# STM32MP25_CM33 register map
File version: 1.3
CPU: CM33 r0p1, little endian, MPU, FPU, vendor SysTick, 8 interrupt priority bits
Registers are 32-bit, read-write, reset 0x0 unless marked. A register's access mark holds for its fields unless they carry their own. Offsets are from the block's base; [hi:lo] are bit positions; {n}, {i} and the like mark numbered series.

## I2C1 — I2C address block description
Base 0x40120000
Same registers: I2C2 0x40130000, I2C3 0x40140000, I2C4 0x40150000, I2C5 0x40160000, I2C6 0x40170000, I2C7 0x40180000, I2C8 0x46040000, I2C1_S 0x50120000, I2C2_S 0x50130000, I2C3_S 0x50140000, I2C4_S 0x50150000, I2C5_S 0x50160000, I2C6_S 0x50170000, I2C7_S 0x50180000, I2C8_S 0x56040000
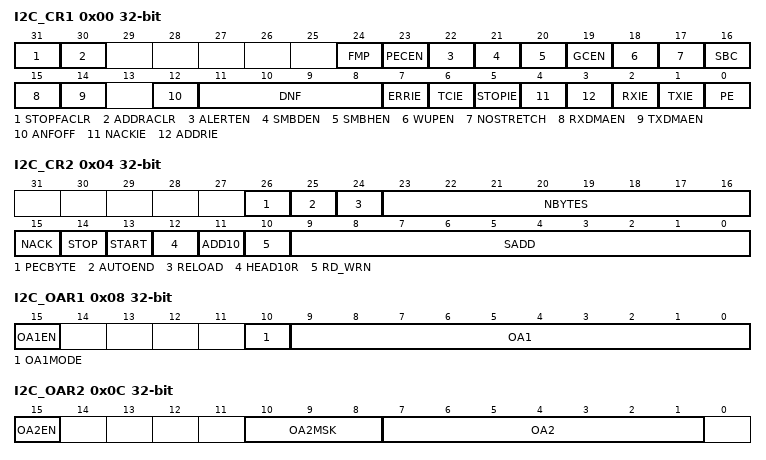
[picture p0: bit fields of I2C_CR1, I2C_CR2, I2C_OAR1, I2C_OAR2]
0x00 I2C_CR1 — I2C control register 1
  [31] STOPFACLR — STOP detection flag (STOPF) automatic clear
    0=STOPF flag is set by hardware, cleared by software by setting STOPCF bit; 1=STOPF flag remains cleared by hardware. This mode can be used in NOSTRETCH slave mode, to avoid the overrun error if the STOPF flag is not cleared before next data transmission. This allows a slave data management by DMA only, without any interrupt from peripheral.
  [30] ADDRACLR — Address match flag (ADDR) automatic clear
    0=ADDR flag is set by hardware, cleared by software by setting ADDRCF bit; 1=ADDR flag remains cleared by hardware. This mode can be used in slave mode, to avoid the ADDR clock stretching if the I2C enables only one slave address. This allows a slave data management by DMA only, without any interrupt from peripheral.
  [24] FMP — Fast-mode Plus 20 mA drive enable
    0=20 mA I/O drive disabled; 1=20 mA I/O drive enabled
  [23] PECEN — PEC enable Note: If the SMBus feature is not supported, this bit is reserved and forced by hardware to 0. Refer to Section75.3.
    0=PEC calculation disabled; 1=PEC calculation enabled
  [22] ALERTEN — SMBus alert enable Note: When ALERTEN = 0, the SMBA pin can be used as a standard GPIO. Note: If the SMBus feature is not supported, this bit is reserved and forced by hardware to 0. Refer to Section75.3.
    0=The SMBus alert pin (SMBA) is not supported in host mode (SMBHEN = 1). In device mode (SMBHEN = 0), the SMBA pin is released and the Alert Response Address header is disabled (0001100x followed by NACK).; 1=The SMBus alert pin is supported in host mode (SMBHEN = 1). In device mode (SMBHEN = 0), the SMBA pin is driven low and the Alert Response Address header is enabled (0001100x followed by ACK).
  [21] SMBDEN — SMBus device default address enable Note: If the SMBus feature is not supported, this bit is reserved and forced by hardware to 0. Refer to Section75.3.
    0=Device default address disabled. Address 0b1100001x is NACKed.; 1=Device default address enabled. Address 0b1100001x is ACKed.
  [20] SMBHEN — SMBus host address enable Note: If the SMBus feature is not supported, this bit is reserved and forced by hardware to 0. Refer to Section75.3.
    0=Host address disabled. Address 0b0001000x is NACKed.; 1=Host address enabled. Address 0b0001000x is ACKed.
  [19] GCEN — General call enable
    0=General call disabled. Address 0b00000000 is NACKed.; 1=General call enabled. Address 0b00000000 is ACKed.
  [18] WUPEN — Wake-up from Stop mode enable Note: If the wake-up from Stop mode feature is not supported, this bit is reserved and forced by hardware to 0. Refer to Section75.3. Note: WUPEN can be set only when DNF = 0000.
    0=Wake-up from Stop mode disabled; 1=Wake-up from Stop mode enabled
  [17] NOSTRETCH — Clock stretching disable This bit is used to disable clock stretching in slave mode. It must be kept cleared in master mode. Note: This bit can be programmed only when the I2C is disabled (PE = 0).
    0=Clock stretching enabled; 1=Clock stretching disabled
  [16] SBC — Slave byte control This bit is used to enable hardware byte control in slave mode.
    0=Slave byte control disabled; 1=Slave byte control enabled
  [15] RXDMAEN — DMA reception requests enable
    0=DMA mode disabled for reception; 1=DMA mode enabled for reception
  [14] TXDMAEN — DMA transmission requests enable
    0=DMA mode disabled for transmission; 1=DMA mode enabled for transmission
  [12] ANFOFF — Analog noise filter OFF Note: This bit can be programmed only when the I2C is disabled (PE = 0).
    0=Analog noise filter enabled; 1=Analog noise filter disabled
  [11:8] DNF — Digital noise filter These bits are used to configure the digital noise filter on SDA and SCL input. The digital filter, filters spikes with a length of up to DNF[3:0] * tsubI2CCLK/sub ... Note: If the analog filter is enabled, the digital filter is added to it. This filter can be programmed only when the I2C is disabled (PE = 0).
    0=Digital filter disabled; 1=Digital filter enabled and filtering capability up to one tsubI2CCLK/sub; 15=digital filter enabled and filtering capability up to fifteen tsubI2CCLK/sub
  [7] ERRIE — Error interrupts enable Note: Any of these errors generates an interrupt: Note: Arbitration loss (ARLO) Note: Bus error detection (BERR) Note: Overrun/underrun (OVR) Note: Timeout detection (TIMEOUT) Note: PEC error detection (PECERR) Note: Alert pin event detection (ALERT)
    0=Error detection interrupts disabled; 1=Error detection interrupts enabled
  [6] TCIE — Transfer complete interrupt enable Note: Any of these events generates an interrupt: Note: Transfer complete (TC) Note: Transfer complete reload (TCR)
    0=Transfer complete interrupt disabled; 1=Transfer complete interrupt enabled
  [5] STOPIE — Stop detection interrupt enable
    0=Stop detection (STOPF) interrupt disabled; 1=Stop detection (STOPF) interrupt enabled
  [4] NACKIE — Not acknowledge received interrupt enable
    0=Not acknowledge (NACKF) received interrupts disabled; 1=Not acknowledge (NACKF) received interrupts enabled
  [3] ADDRIE — Address match interrupt enable (slave only)
    0=Address match (ADDR) interrupts disabled; 1=Address match (ADDR) interrupts enabled
  [2] RXIE — RX interrupt enable
    0=Receive (RXNE) interrupt disabled; 1=Receive (RXNE) interrupt enabled
  [1] TXIE — TX interrupt enable
    0=Transmit (TXIS) interrupt disabled; 1=Transmit (TXIS) interrupt enabled
  [0] PE — Peripheral enable Note: When PE = 0, the I2C SCL and SDA lines are released. Internal state machines and status bits are put back to their reset value. When cleared, PE must be kept low for at least three APB clock cycles.
    0=Peripheral disabled; 1=Peripheral enabled
0x04 I2C_CR2 — I2C control register 2
  [26] PECBYTE — Packet error checking byte This bit is set by software, and cleared by hardware when the PEC is transferred, or when a STOP condition or an Address matched is received, also when PE = 0. Note: Writing 0 to this bit has no effect. Note: This bit has no effect when RELOAD is set, and in slave mode when SBC = 0. Note: If the SMBus feature is not supported, this bit is reserved and forced by hardware to 0. Refer to Section75.3.
    0=No PEC transfer; 1=PEC transmission/reception is requested
  [25] AUTOEND — Automatic end mode (master mode) This bit is set and cleared by software. Note: This bit has no effect in slave mode or when the RELOAD bit is set.
    0=software end mode: TC flag is set when NBYTES data are transferred, stretching SCL low; 1=Automatic end mode: a STOP condition is automatically sent when NBYTES data are transferred
  [24] RELOAD — NBYTES reload mode This bit is set and cleared by software.
    0=The transfer is completed after the NBYTES data transfer (STOP or RESTART follows); 1=The transfer is not completed after the NBYTES data transfer (NBYTES is reloaded). TCR flag is set when NBYTES data are transferred, stretching SCL low.
  [23:16] NBYTES — Number of bytes The number of bytes to be transmitted/received is programmed there. This field is don’t care in slave mode with SBC = 0. Note: Changing these bits when the START bit is set is not allowed.
  [15] NACK — NACK generation (slave mode) The bit is set by software, cleared by hardware when the NACK is sent, or when a STOP condition or an Address matched is received, or when PE = 0. Note: Writing 0 to this bit has no effect. Note: This bit is used only in slave mode: in master receiver mode, NACK is automatically generated after last byte preceding STOP or RESTART condition, whatever the NACK bit value. Note: When an overrun occurs in slave receiver NOSTRETCH mode, a NACK is automatically generated, whatever the NACK bit value. Note: When hardware PEC checking is enabled (PECBYTE = 1), the PEC acknowledge value does not depend on the NACK value.
    0=an ACK is sent after current received byte; 1=a NACK is sent after current received byte
  [14] STOP — Stop generation (master mode) The bit is set by software, cleared by hardware when a STOP condition is detected, or when PE = 0. In master mode: Note: Writing 0 to this bit has no effect.
    0=No Stop generation; 1=Stop generation after current byte transfer
  [13] START — Start generation This bit is set by software, and cleared by hardware after the Start followed by the address sequence is sent, by an arbitration loss, by an address matched in slave mode, by a timeout error detection, or when PE = 0. If the I2C is already in master mode with AUTOEND = 0, setting this bit generates a Repeated start condition when RELOAD = 0, after the end of the NBYTES transfer. Otherwise, setting this bit generates a START condition once the bus is free. Note: Writing 0 to this bit has no effect. Note: The START bit can be set even if the bus is BUSY or I2C is in slave mode. Note: This bit has no effect when RELOAD is set.
    0=No Start generation; 1=Restart/Start generation:
  [12] HEAD10R — 10-bit address header only read direction (master receiver mode) Note: Changing this bit when the START bit is set is not allowed.
    0=The master sends the complete 10-bit slave address read sequence: Start + 2 bytes 10-bit address in write direction + restart + first seven bits of the 10-bit address in read direction; 1=The master sends only the first seven bits of the 10-bit address, followed by read direction
  [11] ADD10 — 10-bit addressing mode (master mode) Note: Changing this bit when the START bit is set is not allowed.
    0=The master operates in 7-bit addressing mode; 1=The master operates in 10-bit addressing mode
  [10] RD_WRN — Transfer direction (master mode) Note: Changing this bit when the START bit is set is not allowed.
    0=Master requests a write transfer; 1=Master requests a read transfer
  [9:0] SADD — Slave address (master mode) In 7-bit addressing mode (ADD10 = 0): SADD[7:1] must be written with the 7-bit slave address to be sent. Bits SADD[9], SADD[8] and SADD[0] are don't care. In 10-bit addressing mode (ADD10 = 1): SADD[9:0] must be written with the 10-bit slave address to be sent. Note: Changing these bits when the START bit is set is not allowed.
0x08 I2C_OAR1 — I2C own address 1 register
  [15] OA1EN — Own address 1 enable
    0=Own address 1 disabled. The received slave address OA1 is NACKed.; 1=Own address 1 enabled. The received slave address OA1 is ACKed.
  [10] OA1MODE — Own address 1 10-bit mode Note: This bit can be written only when OA1EN = 0.
    0=Own address 1 is a 7-bit address; 1=Own address 1 is a 10-bit address
  [9:0] OA1 — Interface own slave address 7-bit addressing mode: OA1[7:1] contains the 7-bit own slave address. Bits OA1[9], OA1[8] and OA1[0] are don't care. 10-bit addressing mode: OA1[9:0] contains the 10-bit own slave address. Note: These bits can be written only when OA1EN = 0.
0x0C I2C_OAR2 — I2C own address 2 register
  [15] OA2EN — Own address 2 enable
    0=Own address 2 disabled. The received slave address OA2 is NACKed.; 1=Own address 2 enabled. The received slave address OA2 is ACKed.
  [10:8] OA2MSK — Own address 2 masks Note: These bits can be written only when OA2EN = 0. Note: As soon as OA2MSK different 0, the reserved I2C addresses (0b0000xxx and 0b1111xxx) are not acknowledged, even if the comparison matches.
    0=No mask; 1=OA2[1] is masked and don’t care. Only OA2[7:2] are compared.; {v}=OA2[{v}:1] are masked and don’t care. Only OA2[7:{v+1}] are compared. (v=2..5); 6=OA2[6:1] are masked and don’t care. Only OA2[7] is compared.; 7=OA2[7:1] are masked and don’t care. No comparison is done, and all (except reserved) 7-bit received addresses are acknowledged.
  [7:1] OA2 — Interface address 7-bit addressing mode: 7-bit address Note: These bits can be written only when OA2EN = 0.
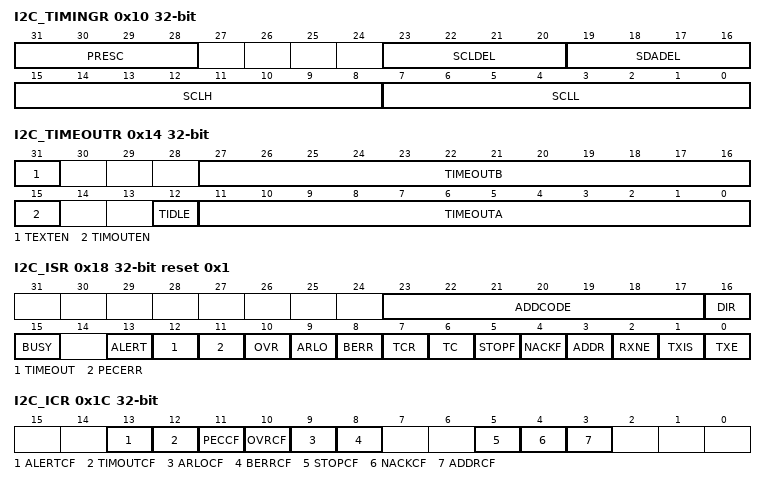
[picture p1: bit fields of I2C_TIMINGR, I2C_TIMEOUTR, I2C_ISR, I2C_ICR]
0x10 I2C_TIMINGR — I2C timing register
  [31:28] PRESC — Timing prescaler This field is used to prescale i2c_ker_ck to generate the clock period tsubPRESC /subused for data setup and hold counters (refer to I2C timings), and for SCL high and low level counters (refer to I2C master initialization). tsubPRESC /sub= (PRESC + 1) x tsubI2CCLK/sub
  [23:20] SCLDEL — Data setup time This field is used to generate a delay tsubSCLDEL/sub = (SCLDEL + 1) x tsubPRESC/sub between SDA edge and SCL rising edge. In master and in slave modes with NOSTRETCH = 0, the SCL line is stretched low during tsubSCLDEL/sub. Note: tsubSCLDEL/sub is used to generate tsubSU:DAT /subtiming.
  [19:16] SDADEL — Data hold time This field is used to generate the delay tsubSDADEL /subbetween SCL falling edge and SDA edge. In master and in slave modes with NOSTRETCH = 0, the SCL line is stretched low during tsubSDADEL/sub. tsubSDADEL/sub= SDADEL x tsubPRESC/sub Note: SDADEL is used to generate tsubHD:DAT /subtiming.
  [15:8] SCLH — SCL high period (master mode) This field is used to generate the SCL high period in master mode. tsubSCLH /sub= (SCLH + 1) x tsubPRESC/sub Note: SCLH is also used to generate tsubSU:STO /suband tsubHD:STA /subtiming.
  [7:0] SCLL — SCL low period (master mode) This field is used to generate the SCL low period in master mode. tsubSCLL /sub= (SCLL + 1) x tsubPRESC/sub Note: SCLL is also used to generate tsubBUF /suband tsubSU:STA /subtimings.
0x14 I2C_TIMEOUTR — I2C timeout register
  [31] TEXTEN — Extended clock timeout enable
    0=Extended clock timeout detection is disabled; 1=Extended clock timeout detection is enabled. When a cumulative SCL stretch for more than tsubLOW:EXT /subis done by the I2C interface, a timeout error is detected (TIMEOUT = 1).
  [27:16] TIMEOUTB — Bus timeout B This field is used to configure the cumulative clock extension timeout: Master mode: the master cumulative clock low extend time (tsubLOW:MEXT/sub) is detected Slave mode: the slave cumulative clock low extend time (tsubLOW:SEXT/sub) is detected tsubLOW:EXT /sub= (TIMEOUTB + TIDLE = 01) x 2048 x tsubI2CCLK/sub Note: These bits can be written only when TEXTEN = 0.
  [15] TIMOUTEN — Clock timeout enable
    0=SCL timeout detection is disabled; 1=SCL timeout detection is enabled. hen SCL is low for more than tsubTIMEOUT/sub (TIDLE = 0) or high for more than tsubIDLE /sub(TIDLE = 1), a timeout error is detected (TIMEOUT = 1).
  [12] TIDLE — Idle clock timeout detection Note: This bit can be written only when TIMOUTEN = 0.
    0=TIMEOUTA is used to detect SCL low timeout; 1=TIMEOUTA is used to detect both SCL and SDA high timeout (bus idle condition)
  [11:0] TIMEOUTA — Bus timeout A This field is used to configure: The SCL low timeout condition tsubTIMEOUT/sub when TIDLE = 0 tsubTIMEOUT/sub= (TIMEOUTA + 1) x 2048 x tsubI2CCLK/sub The bus idle condition (both SCL and SDA high) when TIDLE = 1 tsubIDLE/sub= (TIMEOUTA + 1) x 4 x tsubI2CCLK/sub Note: These bits can be written only when TIMOUTEN = 0.
0x18 I2C_ISR reset 0x1 — I2C interrupt and status register
  [23:17] ADDCODE ro — Address match code (slave mode) These bits are updated with the received address when an address match event occurs (ADDR = 1). In the case of a 10-bit address, ADDCODE provides the 10-bit header followed by the two MSBs of the address.
  [16] DIR ro — Transfer direction (slave mode) This flag is updated when an address match event occurs (ADDR = 1).
    0=Write transfer, slave enters receiver mode; 1=Read transfer, slave enters transmitter mode
  [15] BUSY ro — Bus busy This flag indicates that a communication is in progress on the bus. It is set by hardware when a START condition is detected, and cleared by hardware when a STOP condition is detected, or when PE = 0.
  [13] ALERT ro — SMBus alert This flag is set by hardware when SMBHEN = 1 (SMBus host configuration), ALERTEN = 1 and an SMBALERT event (falling edge) is detected on SMBA pin. It is cleared by software by setting the ALERTCF bit. Note: This bit is cleared by hardware when PE = 0. Note: If the SMBus feature is not supported, this bit is reserved and forced by hardware to 0. Refer to Section75.3.
  [12] TIMEOUT ro — Timeout or tsubLOW/sub detection flag This flag is set by hardware when a timeout or extended clock timeout occurred. It is cleared by software by setting the TIMEOUTCF bit. Note: This bit is cleared by hardware when PE = 0. Note: If the SMBus feature is not supported, this bit is reserved and forced by hardware to 0. Refer to Section75.3.
  [11] PECERR ro — PEC error in reception This flag is set by hardware when the received PEC does not match with the PEC register content. A NACK is automatically sent after the wrong PEC reception. It is cleared by software by setting the PECCF bit. Note: This bit is cleared by hardware when PE = 0. Note: If the SMBus feature is not supported, this bit is reserved and forced by hardware to 0. Refer to Section75.3.
  [10] OVR ro — Overrun/underrun (slave mode) This flag is set by hardware in slave mode with NOSTRETCH = 1, when an overrun/underrun error occurs. It is cleared by software by setting the OVRCF bit. Note: This bit is cleared by hardware when PE = 0.
  [9] ARLO ro — Arbitration lost This flag is set by hardware in case of arbitration loss. It is cleared by software by setting the ARLOCF bit. Note: This bit is cleared by hardware when PE = 0.
  [8] BERR ro — Bus error This flag is set by hardware when a misplaced Start or STOP condition is detected whereas the peripheral is involved in the transfer. The flag is not set during the address phase in slave mode. It is cleared by software by setting the BERRCF bit. Note: This bit is cleared by hardware when PE = 0.
  [7] TCR ro — Transfer complete reload This flag is set by hardware when RELOAD = 1 and NBYTES data have been transferred. It is cleared by software when NBYTES is written to a non-zero value. Note: This bit is cleared by hardware when PE = 0. Note: This flag is only for master mode, or for slave mode when the SBC bit is set.
  [6] TC ro — Transfer complete (master mode) This flag is set by hardware when RELOAD = 0, AUTOEND = 0 and NBYTES data have been transferred. It is cleared by software when START bit or STOP bit is set. Note: This bit is cleared by hardware when PE = 0.
  [5] STOPF ro — Stop detection flag This flag is set by hardware when a STOP condition is detected on the bus and the peripheral is involved in this transfer: as a master, provided that the STOP condition is generated by the peripheral. as a slave, provided that the peripheral has been addressed previously during this transfer. It is cleared by software by setting the STOPCF bit. Note: This bit is cleared by hardware when PE = 0.
  [4] NACKF ro — Not acknowledge received flag This flag is set by hardware when a NACK is received after a byte transmission. It is cleared by software by setting the NACKCF bit. Note: This bit is cleared by hardware when PE = 0.
  [3] ADDR ro — Address matched (slave mode) This bit is set by hardware as soon as the received slave address matched with one of the enabled slave addresses. It is cleared by software by setting ADDRCF bit. Note: This bit is cleared by hardware when PE = 0.
  [2] RXNE ro — Receive data register not empty (receivers) This bit is set by hardware when the received data is copied into the I2C_RXDR register, and is ready to be read. It is cleared when I2C_RXDR is read. Note: This bit is cleared by hardware when PE = 0.
  [1] TXIS — Transmit interrupt status (transmitters) This bit is set by hardware when the I2C_TXDR register is empty and the data to be transmitted must be written in the I2C_TXDR register. It is cleared when the next data to be sent is written in the I2C_TXDR register. This bit can be written to 1 by software only when NOSTRETCH = 1, to generate a TXIS event (interrupt if TXIE = 1 or DMA request if TXDMAEN = 1). Note: This bit is cleared by hardware when PE = 0.
  [0] TXE — Transmit data register empty (transmitters) This bit is set by hardware when the I2C_TXDR register is empty. It is cleared when the next data to be sent is written in the I2C_TXDR register. This bit can be written to 1 by software in order to flush the transmit data register I2C_TXDR. Note: This bit is set by hardware when PE = 0.
0x1C I2C_ICR wo — I2C interrupt clear register
  [13] ALERTCF — Alert flag clear Note: Writing 1 to this bit clears the ALERT flag in the I2C_ISR register. Note: If the SMBus feature is not supported, this bit is reserved and forced by hardware to 0. Refer to Section75.3.
  [12] TIMOUTCF — Timeout detection flag clear Writing 1 to this bit clears the TIMEOUT flag in the I2C_ISR register. Note: If the SMBus feature is not supported, this bit is reserved and forced by hardware to 0. Refer to Section75.3.
  [11] PECCF — PEC error flag clear Writing 1 to this bit clears the PECERR flag in the I2C_ISR register. Note: If the SMBus feature is not supported, this bit is reserved and forced by hardware to 0. Refer to Section75.3.
  [10] OVRCF — Overrun/underrun flag clear Writing 1 to this bit clears the OVR flag in the I2C_ISR register.
  [9] ARLOCF — Arbitration lost flag clear Writing 1 to this bit clears the ARLO flag in the I2C_ISR register.
  [8] BERRCF — Bus error flag clear Writing 1 to this bit clears the BERRF flag in the I2C_ISR register.
  [5] STOPCF — STOP detection flag clear Writing 1 to this bit clears the STOPF flag in the I2C_ISR register.
  [4] NACKCF — Not acknowledge flag clear Writing 1 to this bit clears the NACKF flag in I2C_ISR register.
  [3] ADDRCF — Address matched flag clear Writing 1 to this bit clears the ADDR flag in the I2C_ISR register. Writing 1 to this bit also clears the START bit in the I2C_CR2 register.
0x20 I2C_PECR ro — I2C PEC register
  [7:0] PEC — Packet error checking register This field contains the internal PEC when PECEN=1. The PEC is cleared by hardware when PE = 0.
0x24 I2C_RXDR ro — I2C receive data register
  [7:0] RXDATA — 8-bit receive data Data byte received from the Isup2/supC bus
0x28 I2C_TXDR — I2C transmit data register
  [7:0] TXDATA — 8-bit transmit data Data byte to be transmitted to the Isup2/supC bus Note: These bits can be written only when TXE = 1.
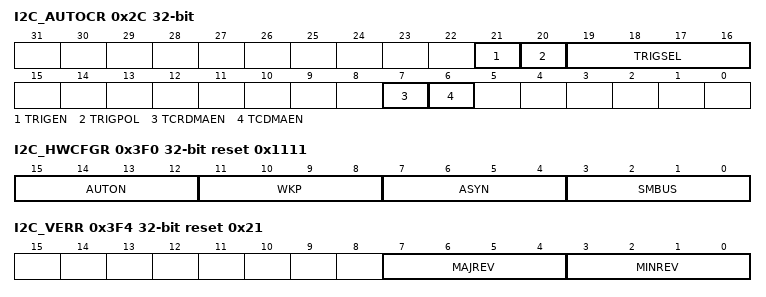
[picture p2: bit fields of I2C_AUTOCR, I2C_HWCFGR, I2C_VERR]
0x2C I2C_AUTOCR — I2C Autonomous mode control register
  [21] TRIGEN — Trigger enable When a trigger is detected, a START condition is sent and the transfer is launched as defined in I2C_CR2.
    0=Trigger disabled; 1=Trigger enabled
  [20] TRIGPOL — Trigger polarity Note: This bit can be written only when PE = 0
    0=Trigger active on rising edge; 1=Trigger active on falling edge
  [19:16] TRIGSEL — Trigger selection (refer to Section75.4.2: I2C pins and internal signals I2C interconnections tables). ... Note: This bit can be written only when PE = 0
    0=i2c_trg0 selected; 1=i2c_trg1 selected; 15=i2c_trg15 selected
  [7] TCRDMAEN — DMA request enable on Transfer Complete Reload event
    0=DMA request not generated on Transfer Complete Reload event; 1=DMA request generated on Transfer Complete Reload event
  [6] TCDMAEN — DMA request enable on Transfer Complete event
    0=DMA request not generated on Transfer Complete event; 1=DMA request generated on Transfer Complete event
0x3F0 I2C_HWCFGR ro reset 0x1111 — I2C hardware configuration register
  [15:12] AUTON
    0=Autonomous mode not implemented; 1=Autonomous mode implemented
  [11:8] WKP
    0=Wake-up from Stop mode not implemented; 1=Wake-up from Stop mode implemented
  [7:4] ASYN
    0=Independent kernel clock not implemented; 1=Independent kernel clock implemented
  [3:0] SMBUS
    0=SMBus mode not implemented; 1=SMBus mode implemented
0x3F4 I2C_VERR ro reset 0x21 — I2C version register
  [7:4] MAJREV — Major revision
  [3:0] MINREV — Minor revision
0x3F8 I2C_IPIDR ro reset 0x130012 — I2C identification register
  [31:0] ID — Identifier.
0x3FC I2C_SIDR ro reset 0xA3C5DD01 — I2C size identification register
  [31:0] SID — Size identifier.
